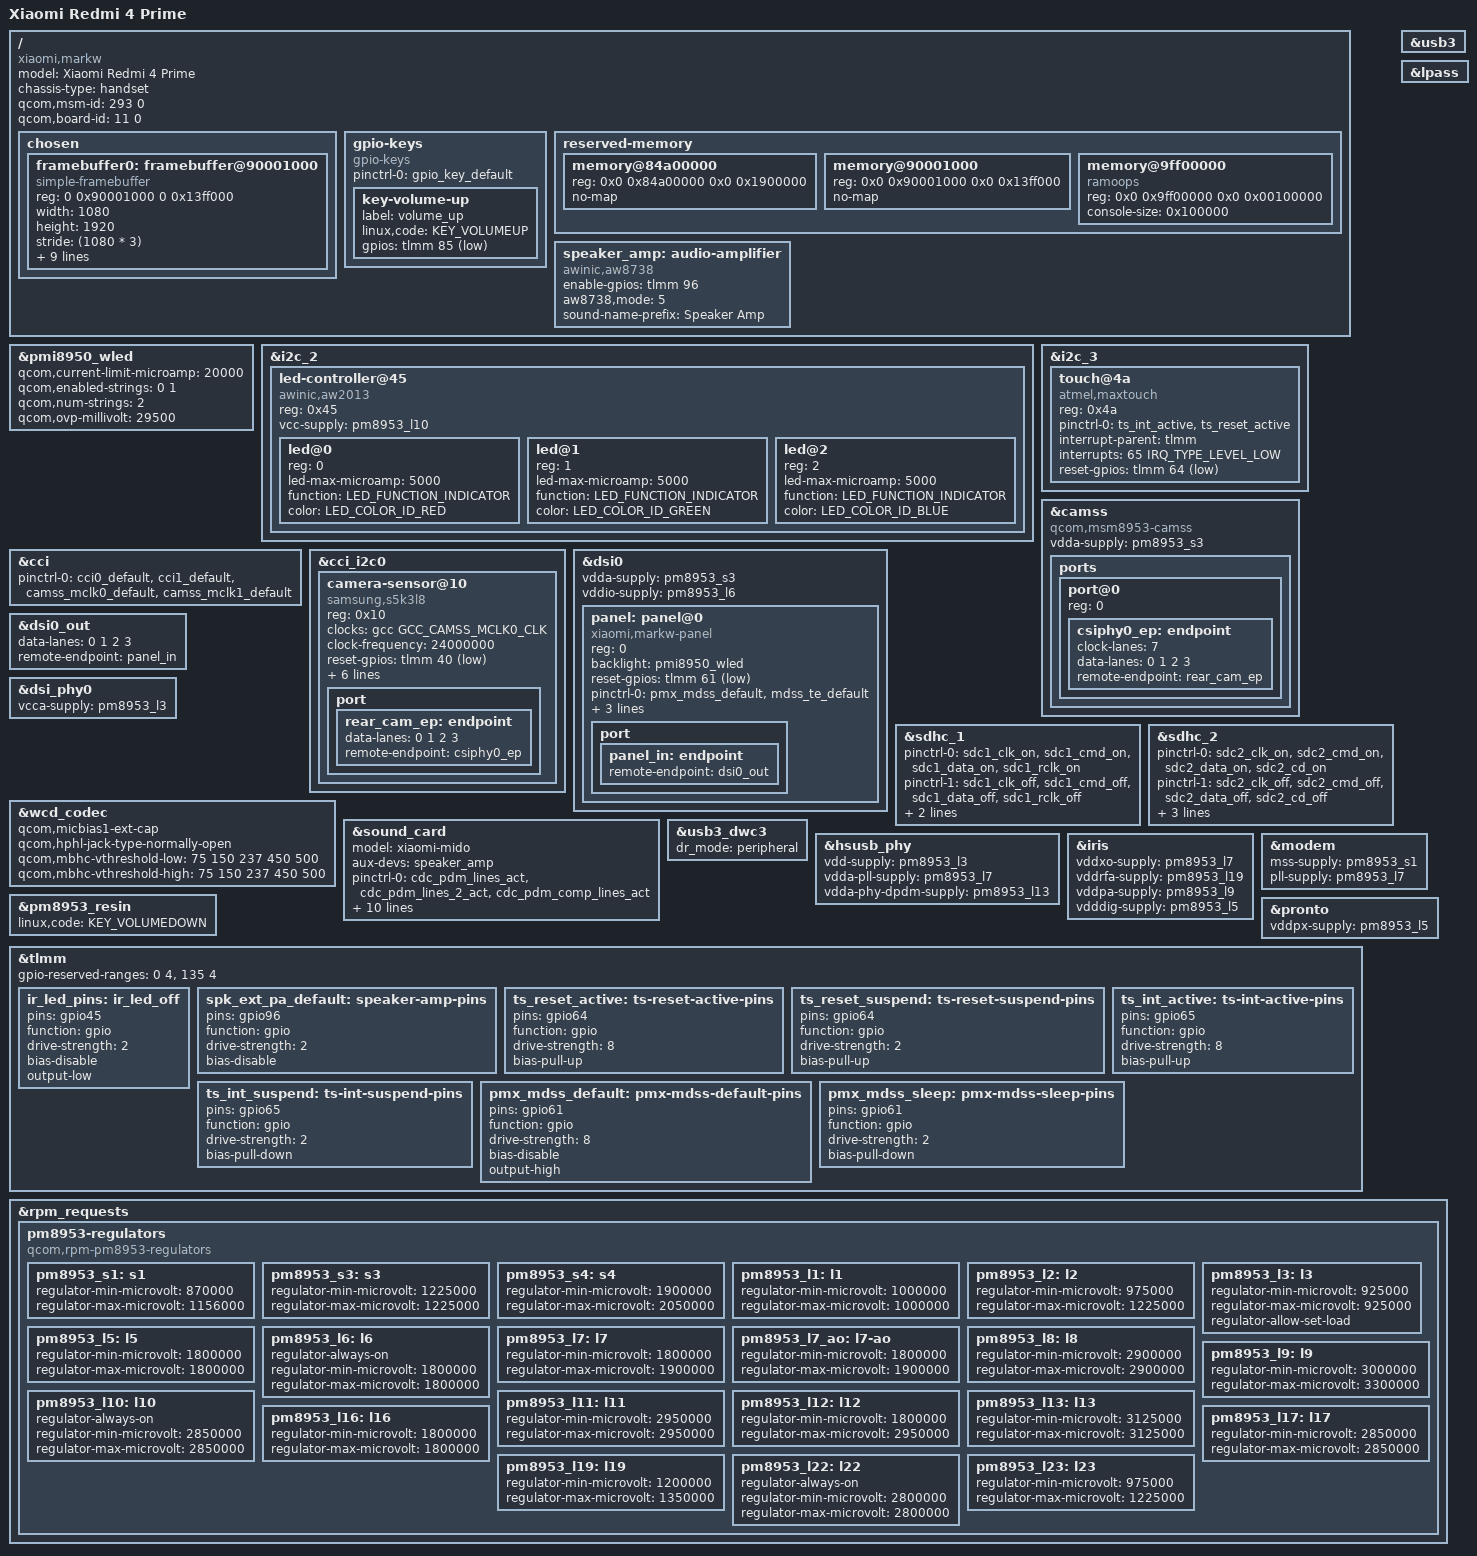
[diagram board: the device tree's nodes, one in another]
/* Copyright (c) 2022 The Linux Foundation. All rights reserved.
 *
 * This program is free software; you can redistribute it and/or modify
 * it under the terms of the GNU General Public License version 2 and
 * only version 2 as published by the Free Software Foundation.
 *
 * This program is distributed in the hope that it will be useful,
 * but WITHOUT ANY WARRANTY; without even the implied warranty of
 * MERCHANTABILITY or FITNESS FOR A PARTICULAR PURPOSE.  See the
 * GNU General Public License for more details.
 */
/dts-v1/;

#include "msm8953.dtsi"
#include "pm8953.dtsi"
#include "pmi8950.dtsi"
#include <dt-bindings/leds/common.h>
#include <dt-bindings/gpio/gpio.h>


/ {
	model = "Xiaomi Redmi 4 Prime";
	compatible = "xiaomi,markw", "qcom,msm8953";
	chassis-type = "handset";
	qcom,msm-id = <293 0>;
	qcom,board-id = <11 0>;

	chosen {
		#address-cells = <2>;
		#size-cells = <2>;
		ranges;

		framebuffer0: framebuffer@90001000 {
			compatible = "simple-framebuffer";
			reg = <0 0x90001000 0 0x13ff000>;

			width = <1080>;
			height = <1920>;
			stride = <(1080 * 3)>;
			format = "r8g8b8";

			power-domains = <&gcc MDSS_GDSC>;

			clocks = <&gcc GCC_MDSS_AHB_CLK>,
				 <&gcc GCC_MDSS_AXI_CLK>,
				 <&gcc GCC_MDSS_VSYNC_CLK>,
				 <&gcc GCC_MDSS_MDP_CLK>,
				 <&gcc GCC_MDSS_BYTE0_CLK>,
				 <&gcc GCC_MDSS_PCLK0_CLK>,
				 <&gcc GCC_MDSS_ESC0_CLK>;
		};
	};

	gpio-keys {
		compatible = "gpio-keys";

		pinctrl-names = "default";
		pinctrl-0 = <&gpio_key_default>;

		key-volume-up {
			label = "volume_up";
			linux,code = <KEY_VOLUMEUP>;
			gpios = <&tlmm 85 GPIO_ACTIVE_LOW>;
		};
	};

	reserved-memory {
		/delete-node/memory@85b00000;

		memory@84a00000 {
			reg = <0x0 0x84a00000 0x0 0x1900000>;
			no-map;
		};

		memory@90001000 {
			reg = <0x0 0x90001000 0x0 0x13ff000>;
			no-map;
		};

		memory@9ff00000 {
			compatible = "ramoops";
			reg = <0x0 0x9ff00000 0x0 0x00100000>;
			console-size = <0x100000>;
		};
	};

	speaker_amp: audio-amplifier {
		compatible = "awinic,aw8738";

		enable-gpios = <&tlmm 96 GPIO_ACTIVE_HIGH>;
		aw8738,mode = <5>;
		sound-name-prefix = "Speaker Amp";
	};
};

&pmi8950_wled {
	status = "okay";

	/* Don't copy-paste! See pmi8950.dtsi */

	qcom,current-limit-microamp = <20000>;
	qcom,enabled-strings = <0 1>;
	qcom,num-strings = <2>;
	qcom,ovp-millivolt = <29500>;
};

&i2c_2 {
	status = "okay";
	led-controller@45 {
		#address-cells = <1>;
		#size-cells = <0>;

		compatible = "awinic,aw2013";

		reg = <0x45>;

		vcc-supply = <&pm8953_l10>;

		led@0 {
			reg = <0>;
			led-max-microamp = <5000>;
			function = LED_FUNCTION_INDICATOR;
			color = <LED_COLOR_ID_RED>;
		};
		led@1 {
			reg = <1>;
			led-max-microamp = <5000>;
			function = LED_FUNCTION_INDICATOR;
			color = <LED_COLOR_ID_GREEN>;
		};
		led@2 {
			reg = <2>;
			led-max-microamp = <5000>;
			function = LED_FUNCTION_INDICATOR;
			color = <LED_COLOR_ID_BLUE>;
		};
	};
};

&i2c_3 {
	status = "okay";	
	
	touch@4a {
		compatible = "atmel,maxtouch";
		reg = <0x4a>;
		pinctrl-names = "default";
		pinctrl-0 = <&ts_int_active &ts_reset_active>;
		interrupt-parent = <&tlmm>;
		interrupts = <65 IRQ_TYPE_LEVEL_LOW>;
		reset-gpios = <&tlmm 64 GPIO_ACTIVE_LOW>;
	};
		
};

&camss {
	status = "okay";
	compatible = "qcom,msm8953-camss";
	vdda-supply = <&pm8953_s3>;

	ports {
		port@0 {
			reg = <0>;
			csiphy0_ep: endpoint {
				clock-lanes = <7>;
				data-lanes = <0 1 2 3>;
				remote-endpoint = <&rear_cam_ep>;
			};
		};
	};
};

&cci {
	pinctrl-names = "default";
	pinctrl-0 = <&cci0_default>,
		    <&cci1_default>,
		    <&camss_mclk0_default>,
		    <&camss_mclk1_default>;

	status = "okay";
};

&cci_i2c0 {
		camera-sensor@10 { // Primary rear camera
		compatible = "samsung,s5k3l8";

		reg = <0x10>;

		clocks = <&gcc GCC_CAMSS_MCLK0_CLK>;
		clock-frequency = <24000000>;

		reset-gpios = <&tlmm 40 GPIO_ACTIVE_LOW>;

		avdd-supply= <&pm8953_l22>;
		dvdd-supply = <&pm8953_l2>;
		vio-supply = <&pm8953_l6>;
		aux-supply = <&pm8953_l17>;
		status = "okay";

		rotation = <270>;
		orientation = <1>;

		port {
			rear_cam_ep: endpoint {
				data-lanes = <0 1 2 3>;
				remote-endpoint = <&csiphy0_ep>;
			};
		};
	};
};

&dsi0 {
	vdda-supply = <&pm8953_s3>;
	vddio-supply = <&pm8953_l6>;

	panel: panel@0 {
		compatible = "xiaomi,markw-panel";
		reg = <0>;

		backlight = <&pmi8950_wled>;

		reset-gpios = <&tlmm 61 GPIO_ACTIVE_LOW>;

		pinctrl-names = "default", "sleep";
		pinctrl-0 = <&pmx_mdss_default &mdss_te_default>;
		pinctrl-1 = <&pmx_mdss_sleep &mdss_te_default>;

		vsp-supply = <&lab_vreg>;
		vsn-supply = <&ibb_vreg>;

		port {
			panel_in: endpoint {
				remote-endpoint = <&dsi0_out>;
			};
		};
	};
};

&dsi0_out {
	data-lanes = <0 1 2 3>;
	remote-endpoint = <&panel_in>;
};

&dsi_phy0 {
	vcca-supply = <&pm8953_l3>;
};


&sdhc_1 {
	status = "okay";

	pinctrl-names = "default", "sleep";
	pinctrl-0 = <&sdc1_clk_on &sdc1_cmd_on &sdc1_data_on  &sdc1_rclk_on>;
	pinctrl-1 = <&sdc1_clk_off &sdc1_cmd_off &sdc1_data_off &sdc1_rclk_off>;
};

&sdhc_2 {
	status = "okay";

	pinctrl-names = "default", "sleep";
	pinctrl-0 = <&sdc2_clk_on &sdc2_cmd_on &sdc2_data_on &sdc2_cd_on>;
	pinctrl-1 = <&sdc2_clk_off &sdc2_cmd_off &sdc2_data_off &sdc2_cd_off>;

	cd-gpios = <&tlmm 133 GPIO_ACTIVE_LOW>;
};

&wcd_codec {
	qcom,micbias1-ext-cap;
	qcom,hphl-jack-type-normally-open;
	qcom,mbhc-vthreshold-low = <75 150 237 450 500>;
	qcom,mbhc-vthreshold-high = <75 150 237 450 500>;
};

&sound_card {
	status = "okay";

	model = "xiaomi-mido";

	aux-devs = <&speaker_amp>;

	pinctrl-names = "default", "sleep";
	pinctrl-0 = <&cdc_pdm_lines_act &cdc_pdm_lines_2_act &cdc_pdm_comp_lines_act>;
	pinctrl-1 = <&cdc_pdm_lines_sus &cdc_pdm_lines_2_sus &cdc_pdm_comp_lines_act>;

	/delete-property/ audio-routing;
	audio-routing =
		"Speaker Amp IN", "LINEOUT_OUT",
		"AMIC1", "MIC BIAS External1",
		"AMIC2", "MIC BIAS Internal2",
		"AMIC3", "MIC BIAS External1",
		"MM_DL1", "MultiMedia1 Playback",
		"MM_DL3", "MultiMedia3 Playback",
		"MM_DL4", "MultiMedia4 Playback",
		"MultiMedia2 Capture", "MM_UL2";
};

&usb3 {
	status = "okay";
};

&usb3_dwc3 {
	dr_mode = "peripheral";
};

&sdhc_1 {
	status = "okay";

	vmmc-supply = <&pm8953_l8>;
	vqmmc-supply = <&pm8953_l5>;
};

&sdhc_2 {
	status = "okay";

	//cd-gpios = <&tlmm 133 GPIO_ACTIVE_LOW>;

	pinctrl-names = "default", "sleep";
	pinctrl-0 = <&sdc2_clk_on &sdc2_cmd_on &sdc2_data_on &sdc2_cd_on>;
	pinctrl-1 = <&sdc2_clk_off &sdc2_cmd_off &sdc2_data_off &sdc2_cd_off>;

	vmmc-supply = <&pm8953_l11>;
	vqmmc-supply = <&pm8953_l12>;
};

&hsusb_phy {
	status = "okay";

	vdd-supply = <&pm8953_l3>;
	vdda-pll-supply = <&pm8953_l7>;
	vdda-phy-dpdm-supply = <&pm8953_l13>;
};


&iris {
	vddxo-supply = <&pm8953_l7>;
	vddrfa-supply = <&pm8953_l19>;
	vddpa-supply = <&pm8953_l9>;
	vdddig-supply = <&pm8953_l5>;

	status = "okay";
};

&lpass {
	status = "okay";
};

&modem {
	status = "okay";

	mss-supply = <&pm8953_s1>;
	pll-supply = <&pm8953_l7>;
};

&pm8953_resin {
	status = "okay";
	linux,code = <KEY_VOLUMEDOWN>;
};

&pronto {
	vddpx-supply = <&pm8953_l5>;
	status = "okay";
};

&tlmm {

	gpio-reserved-ranges = <0 4>, <135 4>;

	ir_led_pins: ir_led_off {
		pins = "gpio45";
		function = "gpio";
		drive-strength = <2>;
		bias-disable;
		output-low;
	
	};
	
	spk_ext_pa_default: speaker-amp-pins {
		pins = "gpio96";
		function = "gpio";
		drive-strength = <2>;
		bias-disable;
	};


	ts_reset_active: ts-reset-active-pins {
		pins = "gpio64";
		function = "gpio";
		drive-strength = <8>;
		bias-pull-up;
	};

	ts_reset_suspend: ts-reset-suspend-pins {
		pins = "gpio64";
		function = "gpio";
		drive-strength = <2>;
		bias-pull-up;
	};
	ts_int_active: ts-int-active-pins {
		pins = "gpio65";
		function = "gpio";
		drive-strength = <8>;
		bias-pull-up;
	};

	ts_int_suspend: ts-int-suspend-pins {
		pins = "gpio65";
		function = "gpio";
		drive-strength = <2>;
		bias-pull-down;
	};

	pmx_mdss_default: pmx-mdss-default-pins {
		pins = "gpio61";
		function = "gpio";
		drive-strength = <8>;
		bias-disable;
		output-high;
	};

	pmx_mdss_sleep: pmx-mdss-sleep-pins {
		pins = "gpio61";
		function = "gpio";
		drive-strength = <2>;
		bias-pull-down;
	};
};


&rpm_requests {
	pm8953-regulators {
		compatible = "qcom,rpm-pm8953-regulators";
		// TODO Add supplies

		pm8953_s1: s1 {
			regulator-min-microvolt = <870000>;
			regulator-max-microvolt = <1156000>;
		};

		pm8953_s3: s3 {
			regulator-min-microvolt = <1225000>;
			regulator-max-microvolt = <1225000>;
		};

		pm8953_s4: s4 {
			regulator-min-microvolt = <1900000>;
			regulator-max-microvolt = <2050000>;
		};

		pm8953_l1: l1 {
			regulator-min-microvolt = <1000000>;
			regulator-max-microvolt = <1000000>;
		};

		pm8953_l2: l2 {
			regulator-min-microvolt = <975000>;
			regulator-max-microvolt = <1225000>;
		};

		pm8953_l3: l3 {
			regulator-min-microvolt = <925000>;
			regulator-max-microvolt = <925000>;
			regulator-allow-set-load;
		};

		pm8953_l5: l5 {
			regulator-min-microvolt = <1800000>;
			regulator-max-microvolt = <1800000>;
		};

		pm8953_l6: l6 {
			regulator-always-on;
			regulator-min-microvolt = <1800000>;
			regulator-max-microvolt = <1800000>;
		};

		pm8953_l7: l7 {
			regulator-min-microvolt = <1800000>;
			regulator-max-microvolt = <1900000>;
		};

		pm8953_l7_ao: l7-ao {
			regulator-min-microvolt = <1800000>;
			regulator-max-microvolt = <1900000>;
		};

		pm8953_l8: l8 {
			regulator-min-microvolt = <2900000>;
			regulator-max-microvolt = <2900000>;
		};

		pm8953_l9: l9 {
			regulator-min-microvolt = <3000000>;
			regulator-max-microvolt = <3300000>;
		};

		pm8953_l10: l10 {
			regulator-always-on;
			regulator-min-microvolt = <2850000>;
			regulator-max-microvolt = <2850000>;
		};

		pm8953_l11: l11 {
			regulator-min-microvolt = <2950000>;
			regulator-max-microvolt = <2950000>;
		};

		pm8953_l12: l12 {
			regulator-min-microvolt = <1800000>;
			regulator-max-microvolt = <2950000>;
		};

		pm8953_l13: l13 {
			regulator-min-microvolt = <3125000>;
			regulator-max-microvolt = <3125000>;
		};

		pm8953_l16: l16 {
			regulator-min-microvolt = <1800000>;
			regulator-max-microvolt = <1800000>;
		};

		pm8953_l17: l17 {
			regulator-min-microvolt = <2850000>;
			regulator-max-microvolt = <2850000>;
		};

		pm8953_l19: l19 {
			regulator-min-microvolt = <1200000>;
			regulator-max-microvolt = <1350000>;
		};

		pm8953_l22: l22 {
			regulator-always-on;
			regulator-min-microvolt = <2800000>;
			regulator-max-microvolt = <2800000>;
		};

		pm8953_l23: l23 {
			regulator-min-microvolt = <975000>;
			regulator-max-microvolt = <1225000>;
		};
	};
};
